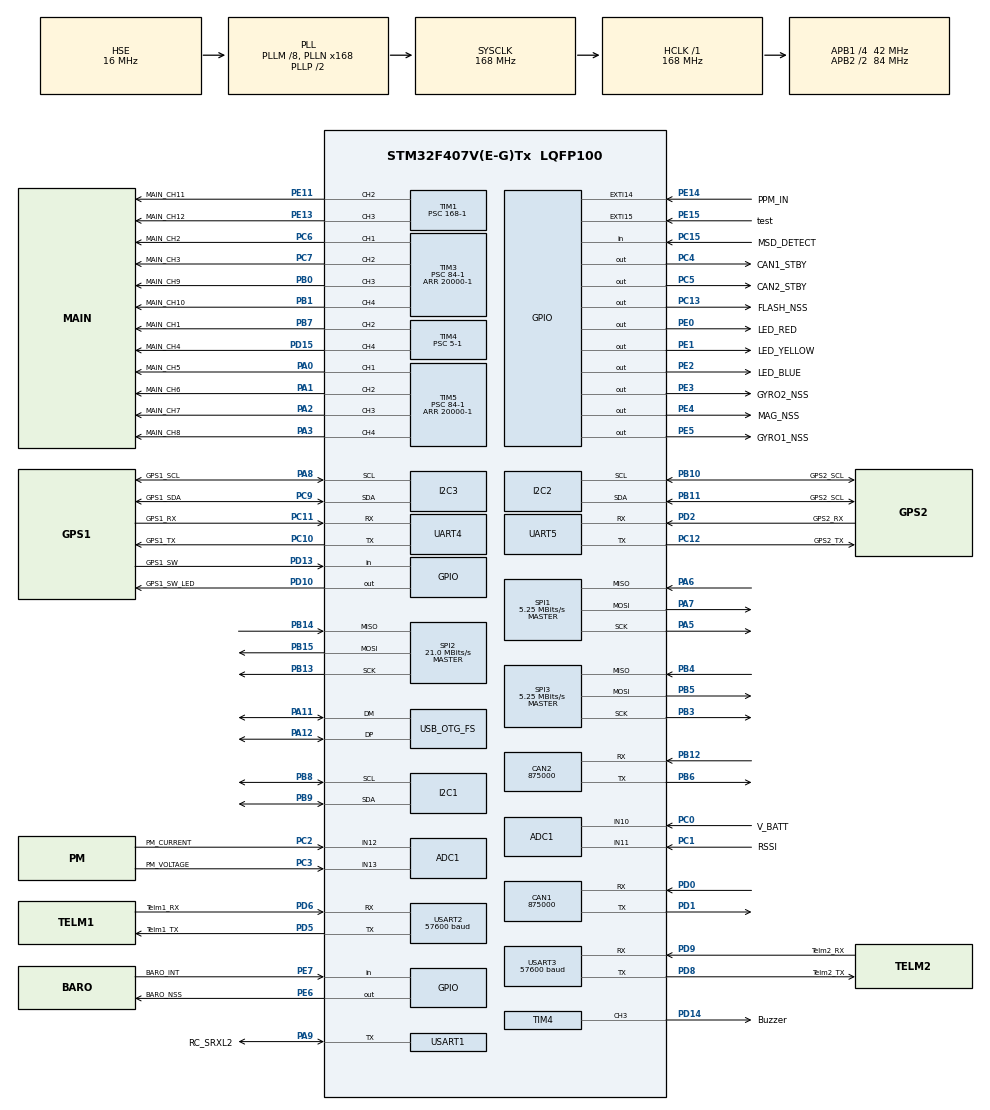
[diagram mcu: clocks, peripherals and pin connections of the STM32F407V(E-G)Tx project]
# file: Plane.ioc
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ADC1.Channel-0\#ChannelRegularConversion=ADC_CHANNEL_11
ADC1.ContinuousConvMode=ENABLE
ADC1.DMAContinuousRequests=ENABLE
ADC1.NbrOfConversion=1
ADC1.NbrOfConversionFlag=1
ADC1.Rank-0\#ChannelRegularConversion=1
ADC1.SamplingTime-0\#ChannelRegularConversion=ADC_SAMPLETIME_3CYCLES
ADC1.master=1
CAN1.CalculateBaudRate=875000
CAN1.CalculateTimeBit=1142
CAN1.CalculateTimeQuantum=380.95238095238096
CAN2.CalculateBaudRate=875000
CAN2.CalculateTimeBit=1142
CAN2.CalculateTimeQuantum=380.95238095238096
Dma.ADC1.0.Direction=DMA_PERIPH_TO_MEMORY
Dma.ADC1.0.FIFOMode=DMA_FIFOMODE_DISABLE
Dma.ADC1.0.Instance=DMA2_Stream0
Dma.ADC1.0.MemDataAlignment=DMA_MDATAALIGN_HALFWORD
Dma.ADC1.0.MemInc=DMA_MINC_ENABLE
Dma.ADC1.0.Mode=DMA_CIRCULAR
Dma.ADC1.0.PeriphDataAlignment=DMA_PDATAALIGN_HALFWORD
Dma.ADC1.0.PeriphInc=DMA_PINC_DISABLE
Dma.ADC1.0.Priority=DMA_PRIORITY_LOW
Dma.Request0=ADC1
Mcu.Family=STM32F4
Mcu.Name=STM32F407V(E-G)Tx
Mcu.Package=LQFP100
NVIC.CAN1_RX0_IRQn=true\:0\:0\:false\:false\:true\:true\:true\:true
NVIC.CAN2_RX0_IRQn=true\:0\:0\:false\:false\:true\:true\:true\:true
NVIC.DMA2_Stream0_IRQn=true\:0\:0\:false\:false\:true\:false\:true\:true
NVIC.I2C1_ER_IRQn=true\:0\:0\:false\:false\:true\:true\:true\:true
NVIC.I2C1_EV_IRQn=true\:0\:0\:false\:false\:true\:true\:true\:true
NVIC.OTG_FS_IRQn=true\:1\:0\:true\:false\:true\:false\:true\:true
NVIC.PriorityGroup=NVIC_PRIORITYGROUP_4
NVIC.TIM8_TRG_COM_TIM14_IRQn=true\:4\:0\:true\:false\:true\:true\:true\:true
NVIC.TIM8_UP_TIM13_IRQn=true\:4\:0\:true\:false\:true\:true\:true\:true
NVIC.UART4_IRQn=true\:0\:0\:false\:false\:true\:true\:true\:true
NVIC.UART5_IRQn=true\:2\:0\:true\:false\:true\:true\:true\:true
NVIC.USART1_IRQn=true\:0\:0\:true\:false\:true\:true\:true\:true
NVIC.USART2_IRQn=true\:2\:0\:true\:false\:true\:true\:true\:true
NVIC.USART3_IRQn=true\:2\:0\:true\:false\:true\:true\:true\:true
PA0-WKUP.GPIO_Label=MAIN_CH5
PA0-WKUP.Signal=S_TIM5_CH1
PA1.GPIO_Label=MAIN_CH6
PA1.Signal=S_TIM5_CH2
PA11.Mode=Device_Only
PA11.Signal=USB_OTG_FS_DM
PA12.Mode=Device_Only
PA12.Signal=USB_OTG_FS_DP
PA13.Mode=Serial_Wire
PA13.Signal=SYS_JTMS-SWDIO
PA14.Mode=Serial_Wire
PA14.Signal=SYS_JTCK-SWCLK
PA2.GPIO_Label=MAIN_CH7
PA2.Signal=S_TIM5_CH3
PA3.GPIO_Label=MAIN_CH8
PA3.Signal=S_TIM5_CH4
PA5.GPIO_Mode=GPIO_MODE_AF_PP
PA5.GPIO_PuPd=GPIO_NOPULL
PA5.Mode=Full_Duplex_Master
PA5.Signal=SPI1_SCK
PA6.Mode=Full_Duplex_Master
PA6.Signal=SPI1_MISO
PA7.Mode=Full_Duplex_Master
PA7.Signal=SPI1_MOSI
PA8.GPIO_Label=GPS1_SCL
PA8.Mode=I2C
PA8.Signal=I2C3_SCL
PA9.GPIO_Label=RC_SRXL2
PA9.GPIO_ModeDefaultOD=GPIO_MODE_AF_PP
PA9.GPIO_PuPd=GPIO_PULLUP
PA9.Mode=Half_duplex(single_wire_mode)
PA9.Signal=USART1_TX
PB0.GPIO_Label=MAIN_CH9
PB0.Signal=S_TIM3_CH3
PB1.GPIO_Label=MAIN_CH10
PB1.Signal=S_TIM3_CH4
PB10.GPIO_Label=GPS2_SCL
PB10.Mode=I2C
PB10.Signal=I2C2_SCL
PB11.GPIO_Label=GPS2_SCL
PB11.Mode=I2C
PB11.Signal=I2C2_SDA
PB12.Mode=CAN_Activate
PB12.Signal=CAN2_RX
PB13.Mode=Full_Duplex_Master
PB13.Signal=SPI2_SCK
PB14.Mode=Full_Duplex_Master
PB14.Signal=SPI2_MISO
PB15.Mode=Full_Duplex_Master
PB15.Signal=SPI2_MOSI
PB3.GPIO_PuPd=GPIO_NOPULL
PB3.Mode=Full_Duplex_Master
PB3.Signal=SPI3_SCK
PB4.GPIO_PuPd=GPIO_NOPULL
PB4.Mode=Full_Duplex_Master
PB4.Signal=SPI3_MISO
PB5.GPIO_PuPd=GPIO_NOPULL
PB5.Mode=Full_Duplex_Master
PB5.Signal=SPI3_MOSI
PB6.Mode=CAN_Activate
PB6.Signal=CAN2_TX
PB7.GPIO_Label=MAIN_CH1
PB7.Signal=S_TIM4_CH2
PB8.Mode=I2C
PB8.Signal=I2C1_SCL
PB9.Mode=I2C
PB9.Signal=I2C1_SDA
PC0.GPIO_Label=V_BATT
PC0.Signal=ADCx_IN10
PC1.GPIO_Label=RSSI
PC1.Signal=ADCx_IN11
PC10.GPIO_Label=GPS1_TX
PC10.Mode=Asynchronous
PC10.Signal=UART4_TX
PC11.GPIO_Label=GPS1_RX
PC11.Mode=Asynchronous
PC11.Signal=UART4_RX
PC12.GPIO_Label=GPS2_TX
PC12.Mode=Asynchronous
PC12.Signal=UART5_TX
PC13-ANTI_TAMP.GPIO_Label=FLASH_NSS
PC13-ANTI_TAMP.Signal=GPIO_Output
PC15-OSC32_OUT.GPIO_Label=MSD_DETECT
PC15-OSC32_OUT.Signal=GPIO_Input
PC2.GPIO_Label=PM_CURRENT
PC2.Signal=ADCx_IN12
PC3.GPIO_Label=PM_VOLTAGE
PC3.Signal=ADCx_IN13
PC4.GPIO_Label=CAN1_STBY
PC4.Signal=GPIO_Output
PC5.GPIO_Label=CAN2_STBY
PC5.Signal=GPIO_Output
PC6.GPIO_Label=MAIN_CH2
PC6.Signal=S_TIM3_CH1
PC7.GPIO_Label=MAIN_CH3
PC7.Signal=S_TIM3_CH2
PC9.GPIO_Label=GPS1_SDA
PC9.Mode=I2C
PC9.Signal=I2C3_SDA
PD0.Mode=CAN_Activate
PD0.Signal=CAN1_RX
PD1.Mode=CAN_Activate
PD1.Signal=CAN1_TX
PD10.GPIO_Label=GPS1_SW_LED 
PD10.Signal=GPIO_Output
PD11.Signal=USART3_CTS
PD12.Signal=USART3_RTS
PD13.GPIO_Label=GPS1_SW
PD13.Signal=GPIO_Input
PD14.GPIO_Label=Buzzer
PD14.Signal=S_TIM4_CH3
PD15.GPIO_Label=MAIN_CH4
PD15.Signal=S_TIM4_CH4
PD2.GPIO_Label=GPS2_RX
PD2.Mode=Asynchronous
PD2.Signal=UART5_RX
PD3.Signal=USART2_CTS
PD4.Signal=USART2_RTS
PD5.GPIO_Label=Telm1_TX
PD5.Mode=Asynchronous
PD5.Signal=USART2_TX
PD6.GPIO_Label=Telm1_RX
PD6.Mode=Asynchronous
PD6.Signal=USART2_RX
PD8.GPIO_Label=Telm2_TX
PD8.Mode=Asynchronous
PD8.Signal=USART3_TX
PD9.GPIO_Label=Telm2_RX
PD9.Mode=Asynchronous
PD9.Signal=USART3_RX
PE0.GPIO_Label=LED_RED
PE0.Signal=GPIO_Output
PE1.GPIO_Label=LED_YELLOW
PE1.Signal=GPIO_Output
PE11.GPIO_Label=MAIN_CH11
PE11.Signal=S_TIM1_CH2
PE13.GPIO_Label=MAIN_CH12
PE13.Signal=S_TIM1_CH3
PE14.GPIO_Label=PPM_IN
PE14.GPIO_PuPd=GPIO_PULLUP
PE14.Signal=GPXTI14
PE15.GPIO_Label=test
PE15.Signal=GPXTI15
PE2.GPIO_Label=LED_BLUE
PE2.Signal=GPIO_Output
PE3.GPIO_Label=GYRO2_NSS
PE3.GPIO_PuPd=GPIO_NOPULL
PE3.Signal=GPIO_Output
PE4.GPIO_Label=MAG_NSS
PE4.Signal=GPIO_Output
PE5.GPIO_Label=GYRO1_NSS
PE5.GPIO_PuPd=GPIO_NOPULL
PE5.Signal=GPIO_Output
PE6.GPIO_Label=BARO_NSS
PE6.GPIO_PuPd=GPIO_NOPULL
PE6.Signal=GPIO_Output
PE7.GPIO_Label=BARO_INT
PE7.Signal=GPIO_Input
PH0-OSC_IN.Mode=HSE-External-Oscillator
PH0-OSC_IN.Signal=RCC_OSC_IN
PH1-OSC_OUT.Mode=HSE-External-Oscillator
PH1-OSC_OUT.Signal=RCC_OSC_OUT
ProjectManager.HeapSize=0x200
ProjectManager.StackSize=0x400
ProjectManager.TargetToolchain=STM32CubeIDE
RCC.48MHZClocksFreq_Value=48000000
RCC.AHBFreq_Value=168000000
RCC.APB1CLKDivider=RCC_HCLK_DIV4
RCC.APB1Freq_Value=42000000
RCC.APB1TimFreq_Value=84000000
RCC.APB2CLKDivider=RCC_HCLK_DIV2
RCC.APB2Freq_Value=84000000
RCC.APB2TimFreq_Value=168000000
RCC.CortexFreq_Value=168000000
RCC.HCLKFreq_Value=168000000
RCC.HSE_VALUE=16000000
RCC.HSI_VALUE=16000000
RCC.LSE_VALUE=32768
RCC.PLLM=8
RCC.PLLN=168
RCC.PLLQ=7
RCC.SYSCLKFreq_VALUE=168000000
RCC.SYSCLKSource=RCC_SYSCLKSOURCE_PLLCLK
RCC.VCOOutputFreq_Value=336000000
SH.ADCx_IN10.0=ADC1_IN10,IN10
SH.ADCx_IN11.0=ADC1_IN11,IN11
SH.ADCx_IN12.0=ADC1_IN12,IN12
SH.ADCx_IN13.0=ADC1_IN13,IN13
SH.S_TIM1_CH2.0=TIM1_CH2,PWM Generation2 CH2
SH.S_TIM1_CH3.0=TIM1_CH3,PWM Generation3 CH3
SH.S_TIM3_CH1.0=TIM3_CH1,PWM Generation1 CH1
SH.S_TIM3_CH2.0=TIM3_CH2,PWM Generation2 CH2
SH.S_TIM3_CH3.0=TIM3_CH3,PWM Generation3 CH3
SH.S_TIM3_CH4.0=TIM3_CH4,PWM Generation4 CH4
SH.S_TIM4_CH2.0=TIM4_CH2,PWM Generation2 CH2
SH.S_TIM4_CH3.0=TIM4_CH3,PWM Generation3 CH3
SH.S_TIM4_CH4.0=TIM4_CH4,PWM Generation4 CH4
SH.S_TIM5_CH1.0=TIM5_CH1,PWM Generation1 CH1
SH.S_TIM5_CH2.0=TIM5_CH2,PWM Generation2 CH2
SH.S_TIM5_CH3.0=TIM5_CH3,PWM Generation3 CH3
SH.S_TIM5_CH4.0=TIM5_CH4,PWM Generation4 CH4
SPI1.BaudRatePrescaler=SPI_BAUDRATEPRESCALER_16
SPI1.CLKPhase=SPI_PHASE_2EDGE
SPI1.CLKPolarity=SPI_POLARITY_HIGH
SPI1.CalculateBaudRate=5.25 MBits/s
SPI1.Direction=SPI_DIRECTION_2LINES
SPI1.Mode=SPI_MODE_MASTER
SPI1.VirtualType=VM_MASTER
SPI2.CalculateBaudRate=21.0 MBits/s
SPI2.Direction=SPI_DIRECTION_2LINES
SPI2.Mode=SPI_MODE_MASTER
SPI2.VirtualType=VM_MASTER
SPI3.BaudRatePrescaler=SPI_BAUDRATEPRESCALER_8
SPI3.CLKPhase=SPI_PHASE_2EDGE
SPI3.CLKPolarity=SPI_POLARITY_HIGH
SPI3.CalculateBaudRate=5.25 MBits/s
SPI3.Direction=SPI_DIRECTION_2LINES
SPI3.Mode=SPI_MODE_MASTER
SPI3.VirtualType=VM_MASTER
TIM1.Channel-PWM\ Generation2\ CH2=TIM_CHANNEL_2
TIM1.Channel-PWM\ Generation3\ CH3=TIM_CHANNEL_3
TIM1.Period=20000-1
TIM1.Prescaler=168-1
TIM1.Pulse-PWM\ Generation2\ CH2=1000-1
TIM1.Pulse-PWM\ Generation3\ CH3=1000-1
TIM13.Channel=TIM_CHANNEL_1
TIM13.Period=42000-1
TIM13.Prescaler=2-1
TIM14.Channel=TIM_CHANNEL_1
TIM14.Period=65535
TIM14.Prescaler=84-1
TIM3.Channel-PWM\ Generation1\ CH1=TIM_CHANNEL_1
TIM3.Channel-PWM\ Generation2\ CH2=TIM_CHANNEL_2
TIM3.Channel-PWM\ Generation3\ CH3=TIM_CHANNEL_3
TIM3.Channel-PWM\ Generation4\ CH4=TIM_CHANNEL_4
TIM3.Period=20000-1
TIM3.Prescaler=84-1
TIM4.Channel-PWM\ Generation2\ CH2=TIM_CHANNEL_2
TIM4.Channel-PWM\ Generation3\ CH3=TIM_CHANNEL_3
TIM4.Channel-PWM\ Generation4\ CH4=TIM_CHANNEL_4
TIM4.Period=64220-1
TIM4.Prescaler=5-1
TIM4.Pulse-PWM\ Generation3\ CH3=0
TIM5.AutoReloadPreload=TIM_AUTORELOAD_PRELOAD_DISABLE
TIM5.Channel-PWM\ Generation1\ CH1=TIM_CHANNEL_1
TIM5.Channel-PWM\ Generation2\ CH2=TIM_CHANNEL_2
TIM5.Channel-PWM\ Generation3\ CH3=TIM_CHANNEL_3
TIM5.Channel-PWM\ Generation4\ CH4=TIM_CHANNEL_4
TIM5.Period=20000-1
TIM5.Prescaler=84-1
TIM5.Pulse-PWM\ Generation1\ CH1=1000-1
TIM5.Pulse-PWM\ Generation2\ CH2=1000-1
TIM5.Pulse-PWM\ Generation3\ CH3=1000-1
TIM5.Pulse-PWM\ Generation4\ CH4=1000-1
UART4.VirtualMode=Asynchronous
UART5.VirtualMode=Asynchronous
USART1.VirtualMode=VM_ASYNC
USART2.BaudRate=57600
USART2.VirtualMode=VM_ASYNC
USART3.BaudRate=57600
USART3.VirtualMode=VM_ASYNC
USB_DEVICE.CLASS_NAME_FS=CDC
USB_DEVICE.USBD_DEBUG_LEVEL-CDC_FS=0
USB_DEVICE.VirtualMode-CDC_FS=Cdc
USB_DEVICE.VirtualModeFS=Cdc_FS
USB_OTG_FS.VirtualMode=Device_Only
VP_TIM13_VS_ClockSourceINT.Mode=Enable_Timer
VP_TIM13_VS_no_output1.Mode=Output Compare1 No Output
VP_TIM14_VS_ClockSourceINT.Mode=Enable_Timer
VP_TIM14_VS_no_output1.Mode=Output Compare1 No Output
VP_TIM1_VS_ClockSourceINT.Mode=Internal
VP_TIM3_VS_ClockSourceINT.Mode=Internal
VP_TIM4_VS_ClockSourceINT.Mode=Internal
VP_TIM5_VS_ClockSourceINT.Mode=Internal
VP_USB_DEVICE_VS_USB_DEVICE_CDC_FS.Mode=CDC_FS
board=custom

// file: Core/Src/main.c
/* USER CODE BEGIN Header */
/**
 ******************************************************************************
 * @file           : main.c
 * @brief          : Main program body
 ******************************************************************************
 * @attention
 *
 * Copyright (c) 2025 STMicroelectronics.
 * All rights reserved.
 *
 * This software is licensed under terms that can be found in the LICENSE file
 * in the root directory of this software component.
 * If no LICENSE file comes with this software, it is provided AS-IS.
 *
 ******************************************************************************
 */
/* USER CODE END Header */
#include "main.h"
#include "usb_device.h"

/* USER CODE BEGIN Includes */
#include "usbd_cdc_if.h"

#include <FC_AHRS/AHRS.h>
#include <FC_Basic/Buzzer/Buzzer.h>
#include <FC_Basic/LED/LED.h>
#include <AP_Failsafe/Failsafe.h>
#include <FC_RC/RC.h>
#include <FC_Serial/MiniLink/MiniLink.h>

#include <FC_Serial/Serial.h>
#include <FC_Servo/Servo.h>
#include <FC_Servo/Servo_module.h>
// 디버깅용 deg 계수
#define RAD2DEG_F (57.29577951308232f)

/* USER CODE END Includes */

/* USER CODE BEGIN PTD */

int _write(int file, char *p, int len) {
#define PRINT_CDC 1
#if PRINT_CDC == 0
	for(int i=0; i<len; i++)
	{
		while(!LL_USART_IsActiveFlag_TXE(USART2));
		LL_USART_TransmitData8(USART2, *(p+i));
	}
#else
	static uint8_t *prePacket = 0;
	static uint16_t preLenth = 0;

	uint8_t *temp = prePacket;
	prePacket = (uint8_t*) malloc((len + preLenth) * sizeof(uint8_t));

	memcpy(prePacket, temp, preLenth);
	memcpy(prePacket + preLenth, p, len);

	free(temp);
	preLenth += len;

	if (USBD_OK == CDC_Transmit_FS((uint8_t*) prePacket, preLenth)) {
		preLenth = 0;
		return preLenth;
	}

	return -1;
#endif
}

/* USER CODE END PTD */

/* USER CODE BEGIN PD */
volatile float roll_deg = 0;
volatile float pitch_deg = 0;
volatile float yaw_deg = 0;

/* USER CODE END PD */

CAN_HandleTypeDef hcan1;
CAN_HandleTypeDef hcan2;

void SystemClock_Config(void);
static void MX_GPIO_Init(void);
static void MX_USART1_UART_Init(void);
static void MX_USART2_UART_Init(void);
static void MX_USART3_UART_Init(void);
static void MX_UART4_Init(void);
static void MX_UART5_Init(void);
static void MX_SPI1_Init(void);
static void MX_SPI2_Init(void);
static void MX_SPI3_Init(void);
static void MX_TIM1_Init(void);
static void MX_TIM3_Init(void);
static void MX_TIM4_Init(void);
static void MX_TIM5_Init(void);
static void MX_TIM13_Init(void);
static void MX_TIM14_Init(void);
static void MX_I2C1_Init(void);
static void MX_I2C2_Init(void);
static void MX_I2C3_Init(void);
static void MX_ADC1_Init(void);
static void MX_CAN1_Init(void);
static void MX_CAN2_Init(void);
/* USER CODE BEGIN PFP */
extern int PARM_load(void);
/* USER CODE END PFP */

/* USER CODE BEGIN 0 */
//rpy test용 스로틀 50 강제주입
static inline void TEST_VirtualRC_Throttle50_NeutralRPY(void) {

	msg.RC_channels.value[0] = 1300; // thr 50%
	msg.RC_channels.value[1] = 1300;
	msg.RC_channels.value[2] = 1300;
	msg.RC_channels.value[3] = 1300;
}

//volatile uint16_t adc_buf[4];
//static inline void PidRiggTest_RC_ADC(void) {
//
//}
// 모터 출력 테스트용
static inline void Test_RawServo_ForMotorTest(void) {
	msg.servo_output_raw.servo_raw[0] = msg.RC_channels.value[param.rc.map.THR];
	msg.servo_output_raw.servo_raw[1] = msg.RC_channels.value[param.rc.map.THR];
	msg.servo_output_raw.servo_raw[2] = msg.RC_channels.value[param.rc.map.THR];
	msg.servo_output_raw.servo_raw[3] = msg.RC_channels.value[param.rc.map.THR];
	setPWM();
}

static uint16_t prev = 0;

void Minilink_Usec_Calculate(void) {
	uint16_t cnt = (uint16_t) TIM14->CNT;
	uint16_t diff = (uint16_t) (cnt - prev);   // wrap 자동 처리
	msg.servo_output_raw.time_usec += (uint32_t) diff;
	prev = cnt;
}

volatile float dbg_dt_imu_max_us = 0.0f;
volatile float dbg_dt_imu_avg_us = 0.0f;
volatile uint32_t dbg_dt_imu_cnt = 0;
volatile uint32_t dbg_err_imu_cnt = 0;
volatile uint32_t dbg_noterr_imu_cnt = 0;
void DTIMU_Check(void) {
	if (!msg.timing.imu_new_sample)
		return;

	if (dbg_dt_imu_cnt < 100) {
		dbg_dt_imu_max_us = 0;
		dbg_dt_imu_cnt++;
		return;
	}
	float dt_us = msg.timing.dt_imu_s;
	// max
	if (dt_us > dbg_dt_imu_max_us) {
		dbg_dt_imu_max_us = dt_us;
	}
	if (dt_us > 0.03) {
		dbg_err_imu_cnt++;
	} else {
		dbg_noterr_imu_cnt++;
	}

	// avg (누적 평균)
	dbg_dt_imu_cnt++;
	dbg_dt_imu_avg_us += (dt_us - dbg_dt_imu_avg_us) / (dbg_dt_imu_cnt + 100);
}

/* USER CODE END 0 */

int main(void) {
	HAL_Init();

	SystemClock_Config();
	MX_GPIO_Init();

	MX_USART1_UART_Init();
	MX_USART2_UART_Init();
	MX_USART3_UART_Init();
	MX_UART4_Init();
	MX_UART5_Init();
	MX_SPI1_Init();
	MX_SPI2_Init();
	MX_SPI3_Init();
	MX_TIM1_Init();
	MX_TIM3_Init();
	MX_TIM4_Init();
	MX_TIM5_Init();
	MX_TIM13_Init();
	MX_TIM14_Init();
	MX_I2C1_Init();
	MX_I2C2_Init();
	MX_I2C3_Init();
	MX_ADC1_Init();
	MX_CAN1_Init();
	MX_CAN2_Init();
	MX_USB_DEVICE_Init();
	LL_TIM_EnableCounter(TIM13); // ms
	LL_TIM_EnableCounter(TIM14);  // us
	LL_TIM_EnableCounter(TIM4);  // 타이머 4번 켬. 타이머4번에 채널3이 부저에 연결되어있음.
	BuzzerPlayInit();

	PARM_load();

	SERIAL_Initialization();

	SERVO_Initialization();

	RC_init();

	AHRS_Initialization();

	LED_SetBlue(1);
	BuzzerPlayOneCycle();

	// doArm은 항상 마지막에
	SERVO_doArm(); // 절대 doArm이후에 buzzer쓰면안됨. 그러면 timer4번이 servo pwm에 씌여서 PSC ARR 바뀌면 안됨.
	while (1) {

		RC_GetData();
		//Minilink_Usec_Calculate(); // 날다 rawservo usec
		AHRS_GetData();
		//스로틀값 작으면 그냥 계산 패스 후 0으로 수정. 이거 없으면 스로틀 최대한 내려도 제어기 때문에 모터 돌아감
		if (FS_IsFailsafe() == 0) { //스로틀값 작으면 그냥 계산 패스 후 0으로 수정. 이거 없으면 스로틀 최대한 내려도 제어기 때문에 모터 돌아감
			SERVO_control();
		}

		roll_deg = msg.attitude.roll * RAD2DEG_F;
		pitch_deg = msg.attitude.pitch * RAD2DEG_F;
		yaw_deg = msg.attitude.yaw * RAD2DEG_F; // rpy degree로 확인용
		LED_Update();
		msg.timing.imu_new_sample = 0; // 매우 중요 imu 값을 읽었다는것. 다음에 또 같은 IMU값 쓰지 않기위함.
	}
}

void SystemClock_Config(void) {
	RCC_OscInitTypeDef RCC_OscInitStruct = { 0 };
	RCC_ClkInitTypeDef RCC_ClkInitStruct = { 0 };

	/** Configure the main internal regulator output voltage
	 */
	__HAL_RCC_PWR_CLK_ENABLE();
	__HAL_PWR_VOLTAGESCALING_CONFIG(PWR_REGULATOR_VOLTAGE_SCALE1);

	/** Initializes the RCC Oscillators according to the specified parameters
	 * in the RCC_OscInitTypeDef structure.
	 */
	RCC_OscInitStruct.OscillatorType = RCC_OSCILLATORTYPE_HSE;
	RCC_OscInitStruct.HSEState = RCC_HSE_ON;
	RCC_OscInitStruct.PLL.PLLState = RCC_PLL_ON;
	RCC_OscInitStruct.PLL.PLLSource = RCC_PLLSOURCE_HSE;
	RCC_OscInitStruct.PLL.PLLM = 8;
	RCC_OscInitStruct.PLL.PLLN = 168;
	RCC_OscInitStruct.PLL.PLLP = RCC_PLLP_DIV2;
	RCC_OscInitStruct.PLL.PLLQ = 7;
	if (HAL_RCC_OscConfig(&RCC_OscInitStruct) != HAL_OK) {
		Error_Handler();
	}

	/** Initializes the CPU, AHB and APB buses clocks
	 */
	RCC_ClkInitStruct.ClockType = RCC_CLOCKTYPE_HCLK | RCC_CLOCKTYPE_SYSCLK
			| RCC_CLOCKTYPE_PCLK1 | RCC_CLOCKTYPE_PCLK2;
	RCC_ClkInitStruct.SYSCLKSource = RCC_SYSCLKSOURCE_PLLCLK;
	RCC_ClkInitStruct.AHBCLKDivider = RCC_SYSCLK_DIV1;
	RCC_ClkInitStruct.APB1CLKDivider = RCC_HCLK_DIV4;
	RCC_ClkInitStruct.APB2CLKDivider = RCC_HCLK_DIV2;

	if (HAL_RCC_ClockConfig(&RCC_ClkInitStruct, FLASH_LATENCY_5) != HAL_OK) {
		Error_Handler();
	}
}

static void MX_ADC1_Init(void) {

	LL_ADC_InitTypeDef ADC_InitStruct = { 0 };
	LL_ADC_REG_InitTypeDef ADC_REG_InitStruct = { 0 };
	LL_ADC_CommonInitTypeDef ADC_CommonInitStruct = { 0 };

	LL_GPIO_InitTypeDef GPIO_InitStruct = { 0 };

	/* Peripheral clock enable */
	LL_APB2_GRP1_EnableClock(LL_APB2_GRP1_PERIPH_ADC1);

	LL_AHB1_GRP1_EnableClock(LL_AHB1_GRP1_PERIPH_GPIOC);
	/**ADC1 GPIO Configuration
	 PC0   ------> ADC1_IN10
	 PC1   ------> ADC1_IN11
	 PC2   ------> ADC1_IN12
	 PC3   ------> ADC1_IN13
	 */
	GPIO_InitStruct.Pin = V_BATT_Pin | RSSI_Pin | PM_CURRENT_Pin
			| PM_VOLTAGE_Pin;
	GPIO_InitStruct.Mode = LL_GPIO_MODE_ANALOG;
	GPIO_InitStruct.Pull = LL_GPIO_PULL_NO;
	LL_GPIO_Init(GPIOC, &GPIO_InitStruct);

	/** Common config
	 */
	ADC_InitStruct.Resolution = LL_ADC_RESOLUTION_12B;
	ADC_InitStruct.DataAlignment = LL_ADC_DATA_ALIGN_RIGHT;
	ADC_InitStruct.SequencersScanMode = LL_ADC_SEQ_SCAN_DISABLE;
	LL_ADC_Init(ADC1, &ADC_InitStruct);
	ADC_REG_InitStruct.TriggerSource = LL_ADC_REG_TRIG_SOFTWARE;
	ADC_REG_InitStruct.SequencerLength = LL_ADC_REG_SEQ_SCAN_DISABLE;
	ADC_REG_InitStruct.SequencerDiscont = LL_ADC_REG_SEQ_DISCONT_DISABLE;
	ADC_REG_InitStruct.ContinuousMode = LL_ADC_REG_CONV_SINGLE;
	ADC_REG_InitStruct.DMATransfer = LL_ADC_REG_DMA_TRANSFER_NONE;
	LL_ADC_REG_Init(ADC1, &ADC_REG_InitStruct);
	LL_ADC_REG_SetFlagEndOfConversion(ADC1, LL_ADC_REG_FLAG_EOC_UNITARY_CONV);
	ADC_CommonInitStruct.CommonClock = LL_ADC_CLOCK_SYNC_PCLK_DIV4;
	ADC_CommonInitStruct.Multimode = LL_ADC_MULTI_INDEPENDENT;
	LL_ADC_CommonInit(__LL_ADC_COMMON_INSTANCE(ADC1), &ADC_CommonInitStruct);

	/** Configure Regular Channel
	 */
	LL_ADC_REG_SetSequencerRanks(ADC1, LL_ADC_REG_RANK_1, LL_ADC_CHANNEL_11);
	LL_ADC_SetChannelSamplingTime(ADC1, LL_ADC_CHANNEL_11,
			LL_ADC_SAMPLINGTIME_3CYCLES);

}

static void MX_CAN1_Init(void) {

	hcan1.Instance = CAN1;
	hcan1.Init.Prescaler = 16;
	hcan1.Init.Mode = CAN_MODE_NORMAL;
	hcan1.Init.SyncJumpWidth = CAN_SJW_1TQ;
	hcan1.Init.TimeSeg1 = CAN_BS1_1TQ;
	hcan1.Init.TimeSeg2 = CAN_BS2_1TQ;
	hcan1.Init.TimeTriggeredMode = DISABLE;
	hcan1.Init.AutoBusOff = DISABLE;
	hcan1.Init.AutoWakeUp = DISABLE;
	hcan1.Init.AutoRetransmission = DISABLE;
	hcan1.Init.ReceiveFifoLocked = DISABLE;
	hcan1.Init.TransmitFifoPriority = DISABLE;
	if (HAL_CAN_Init(&hcan1) != HAL_OK) {
		Error_Handler();
	}

}

static void MX_CAN2_Init(void) {

	hcan2.Instance = CAN2;
	hcan2.Init.Prescaler = 16;
	hcan2.Init.Mode = CAN_MODE_NORMAL;
	hcan2.Init.SyncJumpWidth = CAN_SJW_1TQ;
	hcan2.Init.TimeSeg1 = CAN_BS1_1TQ;
	hcan2.Init.TimeSeg2 = CAN_BS2_1TQ;
	hcan2.Init.TimeTriggeredMode = DISABLE;
	hcan2.Init.AutoBusOff = DISABLE;
	hcan2.Init.AutoWakeUp = DISABLE;
	hcan2.Init.AutoRetransmission = DISABLE;
	hcan2.Init.ReceiveFifoLocked = DISABLE;
	hcan2.Init.TransmitFifoPriority = DISABLE;
	if (HAL_CAN_Init(&hcan2) != HAL_OK) {
		Error_Handler();
	}

}

static void MX_I2C1_Init(void) {

	LL_I2C_InitTypeDef I2C_InitStruct = { 0 };

	LL_GPIO_InitTypeDef GPIO_InitStruct = { 0 };

	LL_AHB1_GRP1_EnableClock(LL_AHB1_GRP1_PERIPH_GPIOB);
	/**I2C1 GPIO Configuration
	 PB8   ------> I2C1_SCL
	 PB9   ------> I2C1_SDA
	 */
	GPIO_InitStruct.Pin = LL_GPIO_PIN_8 | LL_GPIO_PIN_9;
	GPIO_InitStruct.Mode = LL_GPIO_MODE_ALTERNATE;
	GPIO_InitStruct.Speed = LL_GPIO_SPEED_FREQ_VERY_HIGH;
	GPIO_InitStruct.OutputType = LL_GPIO_OUTPUT_OPENDRAIN;
	GPIO_InitStruct.Pull = LL_GPIO_PULL_NO;
	GPIO_InitStruct.Alternate = LL_GPIO_AF_4;
	LL_GPIO_Init(GPIOB, &GPIO_InitStruct);

	/* Peripheral clock enable */
	LL_APB1_GRP1_EnableClock(LL_APB1_GRP1_PERIPH_I2C1);

	/* I2C1 interrupt Init */
	NVIC_SetPriority(I2C1_EV_IRQn,
			NVIC_EncodePriority(NVIC_GetPriorityGrouping(), 0, 0));
	NVIC_EnableIRQ(I2C1_EV_IRQn);
	NVIC_SetPriority(I2C1_ER_IRQn,
			NVIC_EncodePriority(NVIC_GetPriorityGrouping(), 0, 0));
	NVIC_EnableIRQ(I2C1_ER_IRQn);

	/** I2C Initialization
	 */
	LL_I2C_DisableOwnAddress2(I2C1);
	LL_I2C_DisableGeneralCall(I2C1);
	LL_I2C_EnableClockStretching(I2C1);
	I2C_InitStruct.PeripheralMode = LL_I2C_MODE_I2C;
	I2C_InitStruct.ClockSpeed = 100000;
	I2C_InitStruct.DutyCycle = LL_I2C_DUTYCYCLE_2;
	I2C_InitStruct.OwnAddress1 = 0;
	I2C_InitStruct.TypeAcknowledge = LL_I2C_ACK;
	I2C_InitStruct.OwnAddrSize = LL_I2C_OWNADDRESS1_7BIT;
	LL_I2C_Init(I2C1, &I2C_InitStruct);
	LL_I2C_SetOwnAddress2(I2C1, 0);

}

static void MX_I2C2_Init(void) {

	LL_I2C_InitTypeDef I2C_InitStruct = { 0 };

	LL_GPIO_InitTypeDef GPIO_InitStruct = { 0 };

	LL_AHB1_GRP1_EnableClock(LL_AHB1_GRP1_PERIPH_GPIOB);
	/**I2C2 GPIO Configuration
	 PB10   ------> I2C2_SCL
	 PB11   ------> I2C2_SDA
	 */
	GPIO_InitStruct.Pin = GPS2_SCL_Pin | GPS2_SCLB11_Pin;
	GPIO_InitStruct.Mode = LL_GPIO_MODE_ALTERNATE;
	GPIO_InitStruct.Speed = LL_GPIO_SPEED_FREQ_VERY_HIGH;
	GPIO_InitStruct.OutputType = LL_GPIO_OUTPUT_OPENDRAIN;
	GPIO_InitStruct.Pull = LL_GPIO_PULL_NO;
	GPIO_InitStruct.Alternate = LL_GPIO_AF_4;
	LL_GPIO_Init(GPIOB, &GPIO_InitStruct);

	/* Peripheral clock enable */
	LL_APB1_GRP1_EnableClock(LL_APB1_GRP1_PERIPH_I2C2);

	/** I2C Initialization
	 */
	LL_I2C_DisableOwnAddress2(I2C2);
	LL_I2C_DisableGeneralCall(I2C2);
	LL_I2C_EnableClockStretching(I2C2);
	I2C_InitStruct.PeripheralMode = LL_I2C_MODE_I2C;
	I2C_InitStruct.ClockSpeed = 100000;
	I2C_InitStruct.DutyCycle = LL_I2C_DUTYCYCLE_2;
	I2C_InitStruct.OwnAddress1 = 0;
	I2C_InitStruct.TypeAcknowledge = LL_I2C_ACK;
	I2C_InitStruct.OwnAddrSize = LL_I2C_OWNADDRESS1_7BIT;
	LL_I2C_Init(I2C2, &I2C_InitStruct);
	LL_I2C_SetOwnAddress2(I2C2, 0);

}

static void MX_I2C3_Init(void) {

	LL_I2C_InitTypeDef I2C_InitStruct = { 0 };

	LL_GPIO_InitTypeDef GPIO_InitStruct = { 0 };

	LL_AHB1_GRP1_EnableClock(LL_AHB1_GRP1_PERIPH_GPIOC);
	LL_AHB1_GRP1_EnableClock(LL_AHB1_GRP1_PERIPH_GPIOA);
	/**I2C3 GPIO Configuration
	 PC9   ------> I2C3_SDA
	 PA8   ------> I2C3_SCL
	 */
	GPIO_InitStruct.Pin = GPS1_SDA_Pin;
	GPIO_InitStruct.Mode = LL_GPIO_MODE_ALTERNATE;
	GPIO_InitStruct.Speed = LL_GPIO_SPEED_FREQ_VERY_HIGH;
	GPIO_InitStruct.OutputType = LL_GPIO_OUTPUT_OPENDRAIN;
	GPIO_InitStruct.Pull = LL_GPIO_PULL_NO;
	GPIO_InitStruct.Alternate = LL_GPIO_AF_4;
	LL_GPIO_Init(GPS1_SDA_GPIO_Port, &GPIO_InitStruct);

	GPIO_InitStruct.Pin = GPS1_SCL_Pin;
	GPIO_InitStruct.Mode = LL_GPIO_MODE_ALTERNATE;
	GPIO_InitStruct.Speed = LL_GPIO_SPEED_FREQ_VERY_HIGH;
	GPIO_InitStruct.OutputType = LL_GPIO_OUTPUT_OPENDRAIN;
	GPIO_InitStruct.Pull = LL_GPIO_PULL_NO;
	GPIO_InitStruct.Alternate = LL_GPIO_AF_4;
	LL_GPIO_Init(GPS1_SCL_GPIO_Port, &GPIO_InitStruct);

	/* Peripheral clock enable */
	LL_APB1_GRP1_EnableClock(LL_APB1_GRP1_PERIPH_I2C3);

	/** I2C Initialization
	 */
	LL_I2C_DisableOwnAddress2(I2C3);
	LL_I2C_DisableGeneralCall(I2C3);
	LL_I2C_EnableClockStretching(I2C3);
	I2C_InitStruct.PeripheralMode = LL_I2C_MODE_I2C;
	I2C_InitStruct.ClockSpeed = 100000;
	I2C_InitStruct.DutyCycle = LL_I2C_DUTYCYCLE_2;
	I2C_InitStruct.OwnAddress1 = 0;
	I2C_InitStruct.TypeAcknowledge = LL_I2C_ACK;
	I2C_InitStruct.OwnAddrSize = LL_I2C_OWNADDRESS1_7BIT;
	LL_I2C_Init(I2C3, &I2C_InitStruct);
	LL_I2C_SetOwnAddress2(I2C3, 0);

}

static void MX_SPI1_Init(void) {

	LL_SPI_InitTypeDef SPI_InitStruct = { 0 };

	LL_GPIO_InitTypeDef GPIO_InitStruct = { 0 };

	/* Peripheral clock enable */
	LL_APB2_GRP1_EnableClock(LL_APB2_GRP1_PERIPH_SPI1);

	LL_AHB1_GRP1_EnableClock(LL_AHB1_GRP1_PERIPH_GPIOA);
	/**SPI1 GPIO Configuration
	 PA5   ------> SPI1_SCK
	 PA6   ------> SPI1_MISO
	 PA7   ------> SPI1_MOSI
	 */
	GPIO_InitStruct.Pin = LL_GPIO_PIN_5 | LL_GPIO_PIN_6 | LL_GPIO_PIN_7;
	GPIO_InitStruct.Mode = LL_GPIO_MODE_ALTERNATE;
	GPIO_InitStruct.Speed = LL_GPIO_SPEED_FREQ_VERY_HIGH;
	GPIO_InitStruct.OutputType = LL_GPIO_OUTPUT_PUSHPULL;
	GPIO_InitStruct.Pull = LL_GPIO_PULL_NO;
	GPIO_InitStruct.Alternate = LL_GPIO_AF_5;
	LL_GPIO_Init(GPIOA, &GPIO_InitStruct);

	/* SPI1 parameter configuration*/
	SPI_InitStruct.TransferDirection = LL_SPI_FULL_DUPLEX;
	SPI_InitStruct.Mode = LL_SPI_MODE_MASTER;
	SPI_InitStruct.DataWidth = LL_SPI_DATAWIDTH_8BIT;
	SPI_InitStruct.ClockPolarity = LL_SPI_POLARITY_HIGH;
	SPI_InitStruct.ClockPhase = LL_SPI_PHASE_2EDGE;
	SPI_InitStruct.NSS = LL_SPI_NSS_SOFT;
	SPI_InitStruct.BaudRate = LL_SPI_BAUDRATEPRESCALER_DIV16;
	SPI_InitStruct.BitOrder = LL_SPI_MSB_FIRST;
	SPI_InitStruct.CRCCalculation = LL_SPI_CRCCALCULATION_DISABLE;
	SPI_InitStruct.CRCPoly = 10;
	LL_SPI_Init(SPI1, &SPI_InitStruct);
	LL_SPI_SetStandard(SPI1, LL_SPI_PROTOCOL_MOTOROLA);

}

static void MX_SPI2_Init(void) {

	LL_SPI_InitTypeDef SPI_InitStruct = { 0 };

	LL_GPIO_InitTypeDef GPIO_InitStruct = { 0 };

	/* Peripheral clock enable */
	LL_APB1_GRP1_EnableClock(LL_APB1_GRP1_PERIPH_SPI2);

	LL_AHB1_GRP1_EnableClock(LL_AHB1_GRP1_PERIPH_GPIOB);
	/**SPI2 GPIO Configuration
	 PB13   ------> SPI2_SCK
	 PB14   ------> SPI2_MISO
	 PB15   ------> SPI2_MOSI
	 */
	GPIO_InitStruct.Pin = LL_GPIO_PIN_13 | LL_GPIO_PIN_14 | LL_GPIO_PIN_15;
	GPIO_InitStruct.Mode = LL_GPIO_MODE_ALTERNATE;
	GPIO_InitStruct.Speed = LL_GPIO_SPEED_FREQ_VERY_HIGH;
	GPIO_InitStruct.OutputType = LL_GPIO_OUTPUT_PUSHPULL;
	GPIO_InitStruct.Pull = LL_GPIO_PULL_NO;
	GPIO_InitStruct.Alternate = LL_GPIO_AF_5;
	LL_GPIO_Init(GPIOB, &GPIO_InitStruct);

	/* SPI2 parameter configuration*/
	SPI_InitStruct.TransferDirection = LL_SPI_FULL_DUPLEX;
	SPI_InitStruct.Mode = LL_SPI_MODE_MASTER;
	SPI_InitStruct.DataWidth = LL_SPI_DATAWIDTH_8BIT;
	SPI_InitStruct.ClockPolarity = LL_SPI_POLARITY_LOW;
	SPI_InitStruct.ClockPhase = LL_SPI_PHASE_1EDGE;
	SPI_InitStruct.NSS = LL_SPI_NSS_SOFT;
	SPI_InitStruct.BaudRate = LL_SPI_BAUDRATEPRESCALER_DIV2;
	SPI_InitStruct.BitOrder = LL_SPI_MSB_FIRST;
	SPI_InitStruct.CRCCalculation = LL_SPI_CRCCALCULATION_DISABLE;
	SPI_InitStruct.CRCPoly = 10;
	LL_SPI_Init(SPI2, &SPI_InitStruct);
	LL_SPI_SetStandard(SPI2, LL_SPI_PROTOCOL_MOTOROLA);

}

static void MX_SPI3_Init(void) {

	LL_SPI_InitTypeDef SPI_InitStruct = { 0 };

	LL_GPIO_InitTypeDef GPIO_InitStruct = { 0 };

	/* Peripheral clock enable */
	LL_APB1_GRP1_EnableClock(LL_APB1_GRP1_PERIPH_SPI3);

	LL_AHB1_GRP1_EnableClock(LL_AHB1_GRP1_PERIPH_GPIOB);
	/**SPI3 GPIO Configuration
	 PB3   ------> SPI3_SCK
	 PB4   ------> SPI3_MISO
	 PB5   ------> SPI3_MOSI
	 */
	GPIO_InitStruct.Pin = LL_GPIO_PIN_3 | LL_GPIO_PIN_4 | LL_GPIO_PIN_5;
	GPIO_InitStruct.Mode = LL_GPIO_MODE_ALTERNATE;
	GPIO_InitStruct.Speed = LL_GPIO_SPEED_FREQ_VERY_HIGH;
	GPIO_InitStruct.OutputType = LL_GPIO_OUTPUT_PUSHPULL;
	GPIO_InitStruct.Pull = LL_GPIO_PULL_NO;
	GPIO_InitStruct.Alternate = LL_GPIO_AF_6;
	LL_GPIO_Init(GPIOB, &GPIO_InitStruct);

	/* SPI3 parameter configuration*/
	SPI_InitStruct.TransferDirection = LL_SPI_FULL_DUPLEX;
	SPI_InitStruct.Mode = LL_SPI_MODE_MASTER;
	SPI_InitStruct.DataWidth = LL_SPI_DATAWIDTH_8BIT;
	SPI_InitStruct.ClockPolarity = LL_SPI_POLARITY_HIGH;
	SPI_InitStruct.ClockPhase = LL_SPI_PHASE_2EDGE;
	SPI_InitStruct.NSS = LL_SPI_NSS_SOFT;
	SPI_InitStruct.BaudRate = LL_SPI_BAUDRATEPRESCALER_DIV8;
	SPI_InitStruct.BitOrder = LL_SPI_MSB_FIRST;
	SPI_InitStruct.CRCCalculation = LL_SPI_CRCCALCULATION_DISABLE;
	SPI_InitStruct.CRCPoly = 10;
	LL_SPI_Init(SPI3, &SPI_InitStruct);
	LL_SPI_SetStandard(SPI3, LL_SPI_PROTOCOL_MOTOROLA);

}

static void MX_TIM1_Init(void) {

	LL_TIM_InitTypeDef TIM_InitStruct = { 0 };
	LL_TIM_OC_InitTypeDef TIM_OC_InitStruct = { 0 };
	LL_TIM_BDTR_InitTypeDef TIM_BDTRInitStruct = { 0 };

	LL_GPIO_InitTypeDef GPIO_InitStruct = { 0 };

	/* Peripheral clock enable */
	LL_APB2_GRP1_EnableClock(LL_APB2_GRP1_PERIPH_TIM1);

	TIM_InitStruct.Prescaler = 167;
	TIM_InitStruct.CounterMode = LL_TIM_COUNTERMODE_UP;
	TIM_InitStruct.Autoreload = 20000 - LL_TIM_IC_FILTER_FDIV1_N2;
	TIM_InitStruct.ClockDivision = LL_TIM_CLOCKDIVISION_DIV1;
	TIM_InitStruct.RepetitionCounter = 0;
	LL_TIM_Init(TIM1, &TIM_InitStruct);
	LL_TIM_DisableARRPreload(TIM1);
	LL_TIM_SetClockSource(TIM1, LL_TIM_CLOCKSOURCE_INTERNAL);
	LL_TIM_OC_EnablePreload(TIM1, LL_TIM_CHANNEL_CH2);
	TIM_OC_InitStruct.OCMode = LL_TIM_OCMODE_PWM1;
	TIM_OC_InitStruct.OCState = LL_TIM_OCSTATE_DISABLE;
	TIM_OC_InitStruct.OCNState = LL_TIM_OCSTATE_DISABLE;
	TIM_OC_InitStruct.CompareValue = 1000 - LL_TIM_IC_FILTER_FDIV1_N2;
	TIM_OC_InitStruct.OCPolarity = LL_TIM_OCPOLARITY_HIGH;
	TIM_OC_InitStruct.OCNPolarity = LL_TIM_OCPOLARITY_HIGH;
	TIM_OC_InitStruct.OCIdleState = LL_TIM_OCIDLESTATE_LOW;
	TIM_OC_InitStruct.OCNIdleState = LL_TIM_OCIDLESTATE_LOW;
	LL_TIM_OC_Init(TIM1, LL_TIM_CHANNEL_CH2, &TIM_OC_InitStruct);
	LL_TIM_OC_DisableFast(TIM1, LL_TIM_CHANNEL_CH2);
	LL_TIM_OC_EnablePreload(TIM1, LL_TIM_CHANNEL_CH3);
	LL_TIM_OC_Init(TIM1, LL_TIM_CHANNEL_CH3, &TIM_OC_InitStruct);
	LL_TIM_OC_DisableFast(TIM1, LL_TIM_CHANNEL_CH3);
	LL_TIM_SetTriggerOutput(TIM1, LL_TIM_TRGO_RESET);
	LL_TIM_DisableMasterSlaveMode(TIM1);
	TIM_BDTRInitStruct.OSSRState = LL_TIM_OSSR_DISABLE;
	TIM_BDTRInitStruct.OSSIState = LL_TIM_OSSI_DISABLE;
	TIM_BDTRInitStruct.LockLevel = LL_TIM_LOCKLEVEL_OFF;
	TIM_BDTRInitStruct.DeadTime = 0;
	TIM_BDTRInitStruct.BreakState = LL_TIM_BREAK_DISABLE;
	TIM_BDTRInitStruct.BreakPolarity = LL_TIM_BREAK_POLARITY_HIGH;
	TIM_BDTRInitStruct.AutomaticOutput = LL_TIM_AUTOMATICOUTPUT_DISABLE;
	LL_TIM_BDTR_Init(TIM1, &TIM_BDTRInitStruct);
	/* USER CODE BEGIN TIM1_Init 2 */
	LL_TIM_EnableIT_UPDATE(TIM1);

	/* USER CODE END TIM1_Init 2 */
	LL_AHB1_GRP1_EnableClock(LL_AHB1_GRP1_PERIPH_GPIOE);
	/**TIM1 GPIO Configuration
	 PE11   ------> TIM1_CH2
	 PE13   ------> TIM1_CH3
	 */
	GPIO_InitStruct.Pin = MAIN_CH11_Pin | MAIN_CH12_Pin;
	GPIO_InitStruct.Mode = LL_GPIO_MODE_ALTERNATE;
	GPIO_InitStruct.Speed = LL_GPIO_SPEED_FREQ_LOW;
	GPIO_InitStruct.OutputType = LL_GPIO_OUTPUT_PUSHPULL;
	GPIO_InitStruct.Pull = LL_GPIO_PULL_NO;
	GPIO_InitStruct.Alternate = LL_GPIO_AF_1;
	LL_GPIO_Init(GPIOE, &GPIO_InitStruct);

}

static void MX_TIM3_Init(void) {

	LL_TIM_InitTypeDef TIM_InitStruct = { 0 };
	LL_TIM_OC_InitTypeDef TIM_OC_InitStruct = { 0 };

	LL_GPIO_InitTypeDef GPIO_InitStruct = { 0 };

	/* Peripheral clock enable */
	LL_APB1_GRP1_EnableClock(LL_APB1_GRP1_PERIPH_TIM3);

	TIM_InitStruct.Prescaler = 83;
	TIM_InitStruct.CounterMode = LL_TIM_COUNTERMODE_UP;
	TIM_InitStruct.Autoreload = 20000 - LL_TIM_IC_FILTER_FDIV1_N2;
	TIM_InitStruct.ClockDivision = LL_TIM_CLOCKDIVISION_DIV1;
	LL_TIM_Init(TIM3, &TIM_InitStruct);
	LL_TIM_DisableARRPreload(TIM3);
	LL_TIM_SetClockSource(TIM3, LL_TIM_CLOCKSOURCE_INTERNAL);
	LL_TIM_OC_EnablePreload(TIM3, LL_TIM_CHANNEL_CH1);
	TIM_OC_InitStruct.OCMode = LL_TIM_OCMODE_PWM1;
	TIM_OC_InitStruct.OCState = LL_TIM_OCSTATE_DISABLE;
	TIM_OC_InitStruct.OCNState = LL_TIM_OCSTATE_DISABLE;
	TIM_OC_InitStruct.CompareValue = 0;
	TIM_OC_InitStruct.OCPolarity = LL_TIM_OCPOLARITY_HIGH;
	LL_TIM_OC_Init(TIM3, LL_TIM_CHANNEL_CH1, &TIM_OC_InitStruct);
	LL_TIM_OC_DisableFast(TIM3, LL_TIM_CHANNEL_CH1);
	LL_TIM_OC_EnablePreload(TIM3, LL_TIM_CHANNEL_CH2);
	LL_TIM_OC_Init(TIM3, LL_TIM_CHANNEL_CH2, &TIM_OC_InitStruct);
	LL_TIM_OC_DisableFast(TIM3, LL_TIM_CHANNEL_CH2);
	LL_TIM_OC_EnablePreload(TIM3, LL_TIM_CHANNEL_CH3);
	LL_TIM_OC_Init(TIM3, LL_TIM_CHANNEL_CH3, &TIM_OC_InitStruct);
	LL_TIM_OC_DisableFast(TIM3, LL_TIM_CHANNEL_CH3);
	LL_TIM_OC_EnablePreload(TIM3, LL_TIM_CHANNEL_CH4);
	LL_TIM_OC_Init(TIM3, LL_TIM_CHANNEL_CH4, &TIM_OC_InitStruct);
	LL_TIM_OC_DisableFast(TIM3, LL_TIM_CHANNEL_CH4);
	LL_TIM_SetTriggerOutput(TIM3, LL_TIM_TRGO_RESET);
	LL_TIM_DisableMasterSlaveMode(TIM3);
	LL_AHB1_GRP1_EnableClock(LL_AHB1_GRP1_PERIPH_GPIOB);
	LL_AHB1_GRP1_EnableClock(LL_AHB1_GRP1_PERIPH_GPIOC);
	/**TIM3 GPIO Configuration
	 PB0   ------> TIM3_CH3
	 PB1   ------> TIM3_CH4
	 PC6   ------> TIM3_CH1
	 PC7   ------> TIM3_CH2
	 */
	GPIO_InitStruct.Pin = MAIN_CH9_Pin | MAIN_CH10_Pin;
	GPIO_InitStruct.Mode = LL_GPIO_MODE_ALTERNATE;
	GPIO_InitStruct.Speed = LL_GPIO_SPEED_FREQ_LOW;
	GPIO_InitStruct.OutputType = LL_GPIO_OUTPUT_PUSHPULL;
	GPIO_InitStruct.Pull = LL_GPIO_PULL_NO;
	GPIO_InitStruct.Alternate = LL_GPIO_AF_2;
	LL_GPIO_Init(GPIOB, &GPIO_InitStruct);

	GPIO_InitStruct.Pin = MAIN_CH2_Pin | MAIN_CH3_Pin;
	GPIO_InitStruct.Mode = LL_GPIO_MODE_ALTERNATE;
	GPIO_InitStruct.Speed = LL_GPIO_SPEED_FREQ_LOW;
	GPIO_InitStruct.OutputType = LL_GPIO_OUTPUT_PUSHPULL;
	GPIO_InitStruct.Pull = LL_GPIO_PULL_NO;
	GPIO_InitStruct.Alternate = LL_GPIO_AF_2;
	LL_GPIO_Init(GPIOC, &GPIO_InitStruct);

}

static void MX_TIM4_Init(void) {

	LL_TIM_InitTypeDef TIM_InitStruct = { 0 };
	LL_TIM_OC_InitTypeDef TIM_OC_InitStruct = { 0 };

	LL_GPIO_InitTypeDef GPIO_InitStruct = { 0 };

	/* Peripheral clock enable */
	LL_APB1_GRP1_EnableClock(LL_APB1_GRP1_PERIPH_TIM4);

	TIM_InitStruct.Prescaler = 4;
	TIM_InitStruct.CounterMode = LL_TIM_COUNTERMODE_UP;
	TIM_InitStruct.Autoreload = 64220 - LL_TIM_IC_FILTER_FDIV1_N2;
	TIM_InitStruct.ClockDivision = LL_TIM_CLOCKDIVISION_DIV1;
	LL_TIM_Init(TIM4, &TIM_InitStruct);
	LL_TIM_DisableARRPreload(TIM4);
	LL_TIM_SetClockSource(TIM4, LL_TIM_CLOCKSOURCE_INTERNAL);
	LL_TIM_OC_EnablePreload(TIM4, LL_TIM_CHANNEL_CH2);
	TIM_OC_InitStruct.OCMode = LL_TIM_OCMODE_PWM1;
	TIM_OC_InitStruct.OCState = LL_TIM_OCSTATE_DISABLE;
	TIM_OC_InitStruct.OCNState = LL_TIM_OCSTATE_DISABLE;
	TIM_OC_InitStruct.CompareValue = 0;
	TIM_OC_InitStruct.OCPolarity = LL_TIM_OCPOLARITY_HIGH;
	LL_TIM_OC_Init(TIM4, LL_TIM_CHANNEL_CH2, &TIM_OC_InitStruct);
	LL_TIM_OC_DisableFast(TIM4, LL_TIM_CHANNEL_CH2);
	LL_TIM_OC_EnablePreload(TIM4, LL_TIM_CHANNEL_CH3);
	LL_TIM_OC_Init(TIM4, LL_TIM_CHANNEL_CH3, &TIM_OC_InitStruct);
	LL_TIM_OC_DisableFast(TIM4, LL_TIM_CHANNEL_CH3);
	LL_TIM_OC_EnablePreload(TIM4, LL_TIM_CHANNEL_CH4);
	LL_TIM_OC_Init(TIM4, LL_TIM_CHANNEL_CH4, &TIM_OC_InitStruct);
	LL_TIM_OC_DisableFast(TIM4, LL_TIM_CHANNEL_CH4);
	LL_TIM_SetTriggerOutput(TIM4, LL_TIM_TRGO_RESET);
	LL_TIM_DisableMasterSlaveMode(TIM4);
	LL_AHB1_GRP1_EnableClock(LL_AHB1_GRP1_PERIPH_GPIOD);
	LL_AHB1_GRP1_EnableClock(LL_AHB1_GRP1_PERIPH_GPIOB);
	/**TIM4 GPIO Configuration
	 PD14   ------> TIM4_CH3
	 PD15   ------> TIM4_CH4
	 PB7   ------> TIM4_CH2
	 */
	GPIO_InitStruct.Pin = Buzzer_Pin | MAIN_CH4_Pin;
	GPIO_InitStruct.Mode = LL_GPIO_MODE_ALTERNATE;
	GPIO_InitStruct.Speed = LL_GPIO_SPEED_FREQ_LOW;
	GPIO_InitStruct.OutputType = LL_GPIO_OUTPUT_PUSHPULL;
	GPIO_InitStruct.Pull = LL_GPIO_PULL_NO;
	GPIO_InitStruct.Alternate = LL_GPIO_AF_2;
	LL_GPIO_Init(GPIOD, &GPIO_InitStruct);

	GPIO_InitStruct.Pin = MAIN_CH1_Pin;
	GPIO_InitStruct.Mode = LL_GPIO_MODE_ALTERNATE;
	GPIO_InitStruct.Speed = LL_GPIO_SPEED_FREQ_LOW;
	GPIO_InitStruct.OutputType = LL_GPIO_OUTPUT_PUSHPULL;
	GPIO_InitStruct.Pull = LL_GPIO_PULL_NO;
	GPIO_InitStruct.Alternate = LL_GPIO_AF_2;
	LL_GPIO_Init(MAIN_CH1_GPIO_Port, &GPIO_InitStruct);

}

static void MX_TIM5_Init(void) {

	LL_TIM_InitTypeDef TIM_InitStruct = { 0 };
	LL_TIM_OC_InitTypeDef TIM_OC_InitStruct = { 0 };

	LL_GPIO_InitTypeDef GPIO_InitStruct = { 0 };

	/* Peripheral clock enable */
	LL_APB1_GRP1_EnableClock(LL_APB1_GRP1_PERIPH_TIM5);

	TIM_InitStruct.Prescaler = 83;
	TIM_InitStruct.CounterMode = LL_TIM_COUNTERMODE_UP;
	TIM_InitStruct.Autoreload = 20000 - LL_TIM_IC_FILTER_FDIV1_N2;
	TIM_InitStruct.ClockDivision = LL_TIM_CLOCKDIVISION_DIV1;
	LL_TIM_Init(TIM5, &TIM_InitStruct);
	LL_TIM_DisableARRPreload(TIM5);
	LL_TIM_SetClockSource(TIM5, LL_TIM_CLOCKSOURCE_INTERNAL);
	LL_TIM_OC_EnablePreload(TIM5, LL_TIM_CHANNEL_CH1);
	TIM_OC_InitStruct.OCMode = LL_TIM_OCMODE_PWM1;
	TIM_OC_InitStruct.OCState = LL_TIM_OCSTATE_DISABLE;
	TIM_OC_InitStruct.OCNState = LL_TIM_OCSTATE_DISABLE;
	TIM_OC_InitStruct.CompareValue = 1000 - LL_TIM_IC_FILTER_FDIV1_N2;
	TIM_OC_InitStruct.OCPolarity = LL_TIM_OCPOLARITY_HIGH;
	LL_TIM_OC_Init(TIM5, LL_TIM_CHANNEL_CH1, &TIM_OC_InitStruct);
	LL_TIM_OC_DisableFast(TIM5, LL_TIM_CHANNEL_CH1);
	LL_TIM_OC_EnablePreload(TIM5, LL_TIM_CHANNEL_CH2);
	LL_TIM_OC_Init(TIM5, LL_TIM_CHANNEL_CH2, &TIM_OC_InitStruct);
	LL_TIM_OC_DisableFast(TIM5, LL_TIM_CHANNEL_CH2);
	LL_TIM_OC_EnablePreload(TIM5, LL_TIM_CHANNEL_CH3);
	LL_TIM_OC_Init(TIM5, LL_TIM_CHANNEL_CH3, &TIM_OC_InitStruct);
	LL_TIM_OC_DisableFast(TIM5, LL_TIM_CHANNEL_CH3);
	LL_TIM_OC_EnablePreload(TIM5, LL_TIM_CHANNEL_CH4);
	LL_TIM_OC_Init(TIM5, LL_TIM_CHANNEL_CH4, &TIM_OC_InitStruct);
	LL_TIM_OC_DisableFast(TIM5, LL_TIM_CHANNEL_CH4);
	LL_TIM_SetTriggerOutput(TIM5, LL_TIM_TRGO_RESET);
	LL_TIM_DisableMasterSlaveMode(TIM5);
	/* USER CODE BEGIN TIM5_Init 2 */
	LL_TIM_EnableIT_UPDATE(TIM5);

	/* USER CODE END TIM5_Init 2 */
	LL_AHB1_GRP1_EnableClock(LL_AHB1_GRP1_PERIPH_GPIOA);
	/**TIM5 GPIO Configuration
	 PA0-WKUP   ------> TIM5_CH1
	 PA1   ------> TIM5_CH2
	 PA2   ------> TIM5_CH3
	 PA3   ------> TIM5_CH4
	 */
	GPIO_InitStruct.Pin = MAIN_CH5_Pin | MAIN_CH6_Pin | MAIN_CH7_Pin
			| MAIN_CH8_Pin;
	GPIO_InitStruct.Mode = LL_GPIO_MODE_ALTERNATE;
	GPIO_InitStruct.Speed = LL_GPIO_SPEED_FREQ_LOW;
	GPIO_InitStruct.OutputType = LL_GPIO_OUTPUT_PUSHPULL;
	GPIO_InitStruct.Pull = LL_GPIO_PULL_NO;
	GPIO_InitStruct.Alternate = LL_GPIO_AF_2;
	LL_GPIO_Init(GPIOA, &GPIO_InitStruct);

}

static void MX_TIM13_Init(void) {

	LL_TIM_InitTypeDef TIM_InitStruct = { 0 };
	LL_TIM_OC_InitTypeDef TIM_OC_InitStruct = { 0 };

	/* Peripheral clock enable */
	LL_APB1_GRP1_EnableClock(LL_APB1_GRP1_PERIPH_TIM13);

	/* TIM13 interrupt Init */
	NVIC_SetPriority(TIM8_UP_TIM13_IRQn,
			NVIC_EncodePriority(NVIC_GetPriorityGrouping(), 4, 0));
	NVIC_EnableIRQ(TIM8_UP_TIM13_IRQn);

	TIM_InitStruct.Prescaler = 1;
	TIM_InitStruct.CounterMode = LL_TIM_COUNTERMODE_UP;
	TIM_InitStruct.Autoreload = 42000 - LL_TIM_IC_FILTER_FDIV1_N2;
	TIM_InitStruct.ClockDivision = LL_TIM_CLOCKDIVISION_DIV1;
	LL_TIM_Init(TIM13, &TIM_InitStruct);
	LL_TIM_DisableARRPreload(TIM13);
	TIM_OC_InitStruct.OCMode = LL_TIM_OCMODE_FROZEN;
	TIM_OC_InitStruct.OCState = LL_TIM_OCSTATE_DISABLE;
	TIM_OC_InitStruct.OCNState = LL_TIM_OCSTATE_DISABLE;
	TIM_OC_InitStruct.CompareValue = 0;
	TIM_OC_InitStruct.OCPolarity = LL_TIM_OCPOLARITY_HIGH;
	LL_TIM_OC_Init(TIM13, LL_TIM_CHANNEL_CH1, &TIM_OC_InitStruct);
	LL_TIM_OC_DisableFast(TIM13, LL_TIM_CHANNEL_CH1);
	/* USER CODE BEGIN TIM13_Init 2 */
	LL_TIM_EnableIT_UPDATE(TIM13);

	/* USER CODE END TIM13_Init 2 */

}

static void MX_TIM14_Init(void) {

	LL_TIM_InitTypeDef TIM_InitStruct = { 0 };
	LL_TIM_OC_InitTypeDef TIM_OC_InitStruct = { 0 };

	/* Peripheral clock enable */
	LL_APB1_GRP1_EnableClock(LL_APB1_GRP1_PERIPH_TIM14);

	/* TIM14 interrupt Init */
	NVIC_SetPriority(TIM8_TRG_COM_TIM14_IRQn,
			NVIC_EncodePriority(NVIC_GetPriorityGrouping(), 4, 0));
	NVIC_EnableIRQ(TIM8_TRG_COM_TIM14_IRQn);

	TIM_InitStruct.Prescaler = 83;
	TIM_InitStruct.CounterMode = LL_TIM_COUNTERMODE_UP;
	TIM_InitStruct.Autoreload = 65535;
	TIM_InitStruct.ClockDivision = LL_TIM_CLOCKDIVISION_DIV1;
	LL_TIM_Init(TIM14, &TIM_InitStruct);
	LL_TIM_DisableARRPreload(TIM14);
	TIM_OC_InitStruct.OCMode = LL_TIM_OCMODE_FROZEN;
	TIM_OC_InitStruct.OCState = LL_TIM_OCSTATE_DISABLE;
	TIM_OC_InitStruct.OCNState = LL_TIM_OCSTATE_DISABLE;
	TIM_OC_InitStruct.CompareValue = 0;
	TIM_OC_InitStruct.OCPolarity = LL_TIM_OCPOLARITY_HIGH;
	LL_TIM_OC_Init(TIM14, LL_TIM_CHANNEL_CH1, &TIM_OC_InitStruct);
	LL_TIM_OC_DisableFast(TIM14, LL_TIM_CHANNEL_CH1);
	/* USER CODE BEGIN TIM14_Init 2 */
	LL_TIM_EnableIT_UPDATE(TIM14);

	/* USER CODE END TIM14_Init 2 */

}

static void MX_UART4_Init(void) {

	LL_USART_InitTypeDef USART_InitStruct = { 0 };

	LL_GPIO_InitTypeDef GPIO_InitStruct = { 0 };

	/* Peripheral clock enable */
	LL_APB1_GRP1_EnableClock(LL_APB1_GRP1_PERIPH_UART4);

	LL_AHB1_GRP1_EnableClock(LL_AHB1_GRP1_PERIPH_GPIOC);
	/**UART4 GPIO Configuration
	 PC10   ------> UART4_TX
	 PC11   ------> UART4_RX
	 */
	GPIO_InitStruct.Pin = GPS1_TX_Pin | GPS1_RX_Pin;
	GPIO_InitStruct.Mode = LL_GPIO_MODE_ALTERNATE;
	GPIO_InitStruct.Speed = LL_GPIO_SPEED_FREQ_VERY_HIGH;
	GPIO_InitStruct.OutputType = LL_GPIO_OUTPUT_PUSHPULL;
	GPIO_InitStruct.Pull = LL_GPIO_PULL_NO;
	GPIO_InitStruct.Alternate = LL_GPIO_AF_8;
	LL_GPIO_Init(GPIOC, &GPIO_InitStruct);

	/* UART4 interrupt Init */
	NVIC_SetPriority(UART4_IRQn,
			NVIC_EncodePriority(NVIC_GetPriorityGrouping(), 0, 0));
	NVIC_EnableIRQ(UART4_IRQn);

	USART_InitStruct.BaudRate = 115200;
	USART_InitStruct.DataWidth = LL_USART_DATAWIDTH_8B;
	USART_InitStruct.StopBits = LL_USART_STOPBITS_1;
	USART_InitStruct.Parity = LL_USART_PARITY_NONE;
	USART_InitStruct.TransferDirection = LL_USART_DIRECTION_TX_RX;
	USART_InitStruct.HardwareFlowControl = LL_USART_HWCONTROL_NONE;
	USART_InitStruct.OverSampling = LL_USART_OVERSAMPLING_16;
	LL_USART_Init(UART4, &USART_InitStruct);
	LL_USART_ConfigAsyncMode(UART4);
	LL_USART_Enable(UART4);

}

static void MX_UART5_Init(void) {

	LL_USART_InitTypeDef USART_InitStruct = { 0 };

	LL_GPIO_InitTypeDef GPIO_InitStruct = { 0 };

	/* Peripheral clock enable */
	LL_APB1_GRP1_EnableClock(LL_APB1_GRP1_PERIPH_UART5);

	LL_AHB1_GRP1_EnableClock(LL_AHB1_GRP1_PERIPH_GPIOC);
	LL_AHB1_GRP1_EnableClock(LL_AHB1_GRP1_PERIPH_GPIOD);
	/**UART5 GPIO Configuration
	 PC12   ------> UART5_TX
	 PD2   ------> UART5_RX
	 */
	GPIO_InitStruct.Pin = GPS2_TX_Pin;
	GPIO_InitStruct.Mode = LL_GPIO_MODE_ALTERNATE;
	GPIO_InitStruct.Speed = LL_GPIO_SPEED_FREQ_VERY_HIGH;
	GPIO_InitStruct.OutputType = LL_GPIO_OUTPUT_PUSHPULL;
	GPIO_InitStruct.Pull = LL_GPIO_PULL_NO;
	GPIO_InitStruct.Alternate = LL_GPIO_AF_8;
	LL_GPIO_Init(GPS2_TX_GPIO_Port, &GPIO_InitStruct);

	GPIO_InitStruct.Pin = GPS2_RX_Pin;
	GPIO_InitStruct.Mode = LL_GPIO_MODE_ALTERNATE;
	GPIO_InitStruct.Speed = LL_GPIO_SPEED_FREQ_VERY_HIGH;
	GPIO_InitStruct.OutputType = LL_GPIO_OUTPUT_PUSHPULL;
	GPIO_InitStruct.Pull = LL_GPIO_PULL_NO;
	GPIO_InitStruct.Alternate = LL_GPIO_AF_8;
	LL_GPIO_Init(GPS2_RX_GPIO_Port, &GPIO_InitStruct);

	/* UART5 interrupt Init */
	NVIC_SetPriority(UART5_IRQn,
			NVIC_EncodePriority(NVIC_GetPriorityGrouping(), 2, 0));
	NVIC_EnableIRQ(UART5_IRQn);

	USART_InitStruct.BaudRate = 115200;
	USART_InitStruct.DataWidth = LL_USART_DATAWIDTH_8B;
	USART_InitStruct.StopBits = LL_USART_STOPBITS_1;
	USART_InitStruct.Parity = LL_USART_PARITY_NONE;
	USART_InitStruct.TransferDirection = LL_USART_DIRECTION_TX_RX;
	USART_InitStruct.HardwareFlowControl = LL_USART_HWCONTROL_NONE;
	USART_InitStruct.OverSampling = LL_USART_OVERSAMPLING_16;
	LL_USART_Init(UART5, &USART_InitStruct);
	LL_USART_ConfigAsyncMode(UART5);
	LL_USART_Enable(UART5);

}

static void MX_USART1_UART_Init(void)
{

  LL_USART_InitTypeDef USART_InitStruct = {0};

  LL_GPIO_InitTypeDef GPIO_InitStruct = {0};

  /* Peripheral clock enable */
  LL_APB2_GRP1_EnableClock(LL_APB2_GRP1_PERIPH_USART1);

  LL_AHB1_GRP1_EnableClock(LL_AHB1_GRP1_PERIPH_GPIOA);
  /**USART1 GPIO Configuration
  PA9   ------> USART1_TX
  */
  GPIO_InitStruct.Pin = RC_SRXL2_Pin;
  GPIO_InitStruct.Mode = LL_GPIO_MODE_ALTERNATE;
  GPIO_InitStruct.Speed = LL_GPIO_SPEED_FREQ_VERY_HIGH;
  GPIO_InitStruct.OutputType = LL_GPIO_OUTPUT_PUSHPULL;
  GPIO_InitStruct.Pull = LL_GPIO_PULL_UP;
  GPIO_InitStruct.Alternate = LL_GPIO_AF_7;
  LL_GPIO_Init(RC_SRXL2_GPIO_Port, &GPIO_InitStruct);

  /* USART1 interrupt Init */
  NVIC_SetPriority(USART1_IRQn, NVIC_EncodePriority(NVIC_GetPriorityGrouping(),0, 0));
  NVIC_EnableIRQ(USART1_IRQn);

  USART_InitStruct.BaudRate = 420000;
  USART_InitStruct.DataWidth = LL_USART_DATAWIDTH_8B;
  USART_InitStruct.StopBits = LL_USART_STOPBITS_1;
  USART_InitStruct.Parity = LL_USART_PARITY_NONE;
  USART_InitStruct.TransferDirection = LL_USART_DIRECTION_TX_RX;
  USART_InitStruct.OverSampling = LL_USART_OVERSAMPLING_16;
  LL_USART_Init(USART1, &USART_InitStruct);
  LL_USART_Enable(USART1);
  LL_USART_ConfigHalfDuplexMode(USART1);

}

static void MX_USART2_UART_Init(void) {

	LL_USART_InitTypeDef USART_InitStruct = { 0 };

	LL_GPIO_InitTypeDef GPIO_InitStruct = { 0 };

	/* Peripheral clock enable */
	LL_APB1_GRP1_EnableClock(LL_APB1_GRP1_PERIPH_USART2);

	LL_AHB1_GRP1_EnableClock(LL_AHB1_GRP1_PERIPH_GPIOD);
	/**USART2 GPIO Configuration
	 PD3   ------> USART2_CTS
	 PD4   ------> USART2_RTS
	 PD5   ------> USART2_TX
	 PD6   ------> USART2_RX
	 */
	GPIO_InitStruct.Pin = LL_GPIO_PIN_3 | LL_GPIO_PIN_4 | Telm1_TX_Pin
			| Telm1_RX_Pin;
	GPIO_InitStruct.Mode = LL_GPIO_MODE_ALTERNATE;
	GPIO_InitStruct.Speed = LL_GPIO_SPEED_FREQ_VERY_HIGH;
	GPIO_InitStruct.OutputType = LL_GPIO_OUTPUT_PUSHPULL;
	GPIO_InitStruct.Pull = LL_GPIO_PULL_NO;
	GPIO_InitStruct.Alternate = LL_GPIO_AF_7;
	LL_GPIO_Init(GPIOD, &GPIO_InitStruct);

	/* USART2 interrupt Init */
	NVIC_SetPriority(USART2_IRQn,
			NVIC_EncodePriority(NVIC_GetPriorityGrouping(), 2, 0));
	NVIC_EnableIRQ(USART2_IRQn);

	USART_InitStruct.BaudRate = 57600;
	USART_InitStruct.DataWidth = LL_USART_DATAWIDTH_8B;
	USART_InitStruct.StopBits = LL_USART_STOPBITS_1;
	USART_InitStruct.Parity = LL_USART_PARITY_NONE;
	USART_InitStruct.TransferDirection = LL_USART_DIRECTION_TX_RX;
	USART_InitStruct.HardwareFlowControl = LL_USART_HWCONTROL_NONE;
	USART_InitStruct.OverSampling = LL_USART_OVERSAMPLING_16;
	LL_USART_Init(USART2, &USART_InitStruct);
	LL_USART_ConfigAsyncMode(USART2);
	LL_USART_Enable(USART2);

}

static void MX_USART3_UART_Init(void) {

	LL_USART_InitTypeDef USART_InitStruct = { 0 };

	LL_GPIO_InitTypeDef GPIO_InitStruct = { 0 };

	/* Peripheral clock enable */
	LL_APB1_GRP1_EnableClock(LL_APB1_GRP1_PERIPH_USART3);

	LL_AHB1_GRP1_EnableClock(LL_AHB1_GRP1_PERIPH_GPIOD);
	/**USART3 GPIO Configuration
	 PD8   ------> USART3_TX
	 PD9   ------> USART3_RX
	 PD11   ------> USART3_CTS
	 PD12   ------> USART3_RTS
	 */
	GPIO_InitStruct.Pin = Telm2_TX_Pin | Telm2_RX_Pin | LL_GPIO_PIN_11
			| LL_GPIO_PIN_12;
	GPIO_InitStruct.Mode = LL_GPIO_MODE_ALTERNATE;
	GPIO_InitStruct.Speed = LL_GPIO_SPEED_FREQ_VERY_HIGH;
	GPIO_InitStruct.OutputType = LL_GPIO_OUTPUT_PUSHPULL;
	GPIO_InitStruct.Pull = LL_GPIO_PULL_NO;
	GPIO_InitStruct.Alternate = LL_GPIO_AF_7;
	LL_GPIO_Init(GPIOD, &GPIO_InitStruct);

	/* USART3 interrupt Init */
	NVIC_SetPriority(USART3_IRQn,
			NVIC_EncodePriority(NVIC_GetPriorityGrouping(), 2, 0));
	NVIC_EnableIRQ(USART3_IRQn);

	USART_InitStruct.BaudRate = 57600;
	USART_InitStruct.DataWidth = LL_USART_DATAWIDTH_8B;
	USART_InitStruct.StopBits = LL_USART_STOPBITS_1;
	USART_InitStruct.Parity = LL_USART_PARITY_NONE;
	USART_InitStruct.TransferDirection = LL_USART_DIRECTION_TX_RX;
	USART_InitStruct.HardwareFlowControl = LL_USART_HWCONTROL_NONE;
	USART_InitStruct.OverSampling = LL_USART_OVERSAMPLING_16;
	LL_USART_Init(USART3, &USART_InitStruct);
	LL_USART_ConfigAsyncMode(USART3);
	LL_USART_Enable(USART3);

}

static void MX_GPIO_Init(void) {
	LL_EXTI_InitTypeDef EXTI_InitStruct = { 0 };
	LL_GPIO_InitTypeDef GPIO_InitStruct = { 0 };

	/* GPIO Ports Clock Enable */
	LL_AHB1_GRP1_EnableClock(LL_AHB1_GRP1_PERIPH_GPIOE);
	LL_AHB1_GRP1_EnableClock(LL_AHB1_GRP1_PERIPH_GPIOC);
	LL_AHB1_GRP1_EnableClock(LL_AHB1_GRP1_PERIPH_GPIOH);
	LL_AHB1_GRP1_EnableClock(LL_AHB1_GRP1_PERIPH_GPIOA);
	LL_AHB1_GRP1_EnableClock(LL_AHB1_GRP1_PERIPH_GPIOB);
	LL_AHB1_GRP1_EnableClock(LL_AHB1_GRP1_PERIPH_GPIOD);

	/**/
	LL_GPIO_ResetOutputPin(GPIOE,
			LED_BLUE_Pin | GYRO2_NSS_Pin | MAG_NSS_Pin | GYRO1_NSS_Pin
					| BARO_NSS_Pin | LED_RED_Pin | LED_YELLOW_Pin);

	/**/
	LL_GPIO_ResetOutputPin(GPIOC,
			FLASH_NSS_Pin | CAN1_STBY_Pin | CAN2_STBY_Pin);

	/**/
	LL_GPIO_ResetOutputPin(GPS1_SW_LED_GPIO_Port, GPS1_SW_LED_Pin);

	/**/
	GPIO_InitStruct.Pin = LED_BLUE_Pin | GYRO2_NSS_Pin | MAG_NSS_Pin
			| GYRO1_NSS_Pin | BARO_NSS_Pin | LED_RED_Pin | LED_YELLOW_Pin;
	GPIO_InitStruct.Mode = LL_GPIO_MODE_OUTPUT;
	GPIO_InitStruct.Speed = LL_GPIO_SPEED_FREQ_LOW;
	GPIO_InitStruct.OutputType = LL_GPIO_OUTPUT_PUSHPULL;
	GPIO_InitStruct.Pull = LL_GPIO_PULL_NO;
	LL_GPIO_Init(GPIOE, &GPIO_InitStruct);

	/**/
	GPIO_InitStruct.Pin = FLASH_NSS_Pin | CAN1_STBY_Pin | CAN2_STBY_Pin;
	GPIO_InitStruct.Mode = LL_GPIO_MODE_OUTPUT;
	GPIO_InitStruct.Speed = LL_GPIO_SPEED_FREQ_LOW;
	GPIO_InitStruct.OutputType = LL_GPIO_OUTPUT_PUSHPULL;
	GPIO_InitStruct.Pull = LL_GPIO_PULL_NO;
	LL_GPIO_Init(GPIOC, &GPIO_InitStruct);

	/**/
	GPIO_InitStruct.Pin = MSD_DETECT_Pin;
	GPIO_InitStruct.Mode = LL_GPIO_MODE_INPUT;
	GPIO_InitStruct.Pull = LL_GPIO_PULL_NO;
	LL_GPIO_Init(MSD_DETECT_GPIO_Port, &GPIO_InitStruct);

	/**/
	GPIO_InitStruct.Pin = BARO_INT_Pin;
	GPIO_InitStruct.Mode = LL_GPIO_MODE_INPUT;
	GPIO_InitStruct.Pull = LL_GPIO_PULL_NO;
	LL_GPIO_Init(BARO_INT_GPIO_Port, &GPIO_InitStruct);

	/**/
	GPIO_InitStruct.Pin = GPS1_SW_LED_Pin;
	GPIO_InitStruct.Mode = LL_GPIO_MODE_OUTPUT;
	GPIO_InitStruct.Speed = LL_GPIO_SPEED_FREQ_LOW;
	GPIO_InitStruct.OutputType = LL_GPIO_OUTPUT_PUSHPULL;
	GPIO_InitStruct.Pull = LL_GPIO_PULL_NO;
	LL_GPIO_Init(GPS1_SW_LED_GPIO_Port, &GPIO_InitStruct);

	/**/
	GPIO_InitStruct.Pin = GPS1_SW_Pin;
	GPIO_InitStruct.Mode = LL_GPIO_MODE_INPUT;
	GPIO_InitStruct.Pull = LL_GPIO_PULL_NO;
	LL_GPIO_Init(GPS1_SW_GPIO_Port, &GPIO_InitStruct);

	/**/
	LL_SYSCFG_SetEXTISource(LL_SYSCFG_EXTI_PORTE, LL_SYSCFG_EXTI_LINE14);

	/**/
	EXTI_InitStruct.Line_0_31 = LL_EXTI_LINE_14;
	EXTI_InitStruct.LineCommand = ENABLE;
	EXTI_InitStruct.Mode = LL_EXTI_MODE_IT;
	EXTI_InitStruct.Trigger = LL_EXTI_TRIGGER_FALLING;
	LL_EXTI_Init(&EXTI_InitStruct);

	/**/
	LL_GPIO_SetPinPull(PPM_IN_GPIO_Port, PPM_IN_Pin, LL_GPIO_PULL_NO);

	/**/
	LL_GPIO_SetPinMode(PPM_IN_GPIO_Port, PPM_IN_Pin, LL_GPIO_MODE_INPUT);

	/* EXTI interrupt init*/
	NVIC_SetPriority(EXTI15_10_IRQn,
			NVIC_EncodePriority(NVIC_GetPriorityGrouping(), 0, 0));
	NVIC_EnableIRQ(EXTI15_10_IRQn);

	/* USER CODE BEGIN MX_GPIO_Init_2 */
	LL_EXTI_EnableIT_0_31(LL_EXTI_LINE_14);
	LL_EXTI_EnableFallingTrig_0_31(LL_EXTI_LINE_14);
	/* USER CODE END MX_GPIO_Init_2 */
}

void Error_Handler(void) {
	__disable_irq();
	while (1) {
	}
}
